# PIC32MZ2051W104132 device description
Architecture: MIPS; Family: PIC32MZW; Series: PIC32MZW
Registers are 32-bit, read-write, no defined reset value unless marked. A register's access mark holds for its fields unless they carry their own. Offsets are from the block's base; [hi:lo] are bit positions; {n}, {i} and the like mark numbered series.

## CRU
Instances: CRU 0x1f801200 in periph_pb1a
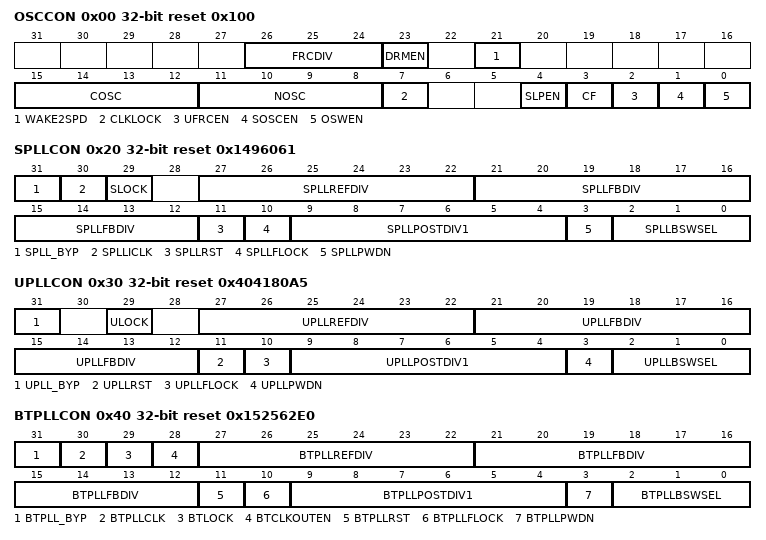
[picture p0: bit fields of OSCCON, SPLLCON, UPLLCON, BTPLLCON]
0x00 OSCCON reset 0x100 — CRU OSCILLATOR CONTROL REGISTER
  [26:24] FRCDIV — Fast RC Clock Divider bits
    0=OSC_FRC_DIV_1 (FRC Divide by 1); 1=OSC_FRC_DIV_2 (FRC Divide by 2); 2=OSC_FRC_DIV_4 (FRC Divide by 4); 3=OSC_FRC_DIV_8 (FRC Divide by 8); 4=OSC_FRC_DIV_16 (FRC Divide by 16); 5=OSC_FRC_DIV_32 (FRC Divide by 32); 6=OSC_FRC_DIV_64 (FRC Divide by 64); 7=OSC_FRC_DIV_256 (FRC Divide by 256)
  [23] DRMEN — Enable Dream Mode bit
    1=SLEEP (When the cpu_si_sleep input is asserted and SLPEN = 1, DMA transfer complete causes SLEEP Mode to be entered); 0=NO_EFFECT (DMA transfer has no effect)
  [21] WAKE2SPD — 2-Speed startup enabled in Sleep mode bit
    1=FRC (When the device EXITS Sleep Mode, the sys_clk will be from FRC until the selected clock is ready); 0=SELECTED_CLK (When the device EXITS Sleep Mode, the sys_clk will be from the selected clock.)
  [15:12] COSC — Current Oscillator Selection bits (Read-only)
    0=FRC (Fast RC Oscillator (FRC) divided by OSCCON.FRCDIV (Supports FRC/16 and FRC/1)); 1=SPLL (System PLL (SPLL Module) (input clock and divider set by SPLLCON)); 2=POSC (Primary Oscillator- POSC); 3=UPLL (USB PLL (UPLL Module) (input clock and divider set by UPLLCON)); 4=SOSC (Secondary Oscillator (SOSC)); 5=LPRC (Low Power RC Oscillator (LPRC)); 6=BTCLK (BT PLL (input clock and divider set by BTPLLCON)); 7=ECLK (EWPLL Ethernet Clock (input clock and divider set by EWPLLCON)); 8=WCLK (EWPLL WiFi Clock (input clock and divider set by EWPLLCON))
  [11:8] NOSC — New Oscillator Selection bits
    0=FRCCLK (Fast RC Oscillator (FRC) divided by OSCCON.FRCDIV ( Supports FRC/16 and FRC/1)); 1=SPLL (SPLL Module (input clock and divider set by SPLLCON)); 2=POSC (Primary Oscillator); 3=USBCLK (UPLL mode (input clock divider set by UPLLCON) -- was POSC with PLL); 4=SOSC (Secondary Oscillator (SOSC)); 5=LPRC (Low Power RC Oscillator (LPRC)); 6=BTCLK (BT PLL (input clock and divider set by BTPLLCON)); 7=ECLK (EWPLL Ethernet Clock (input clock and divider set by EWPLLCON)); 8=WCLK (EWPLL WiFi Clock (input clock and divider set by EWPLLCON))
  [7] CLKLOCK — Clock Lock Enabled bit
    1=LOCKED (All clock and PLL configuration registers are locked. These include OSCCON, OSCTRIM, SPLLCON, UPLLCON, PBxDIV); 0=UNLOCKED (Clock and PLL selection registers are not locked, configurations may be modified)
  [4] SLPEN — Enable SLEEP Mode bit
    1=SLEEP (When a WAIT Instruction is executed device will enter SLEEP Mode); 0=IDLE (When a WAIT instruction is executed device will enter IDLE Mode)
  [3] CF — Clock Fail Detect bit (Read / writable / Clearable by application)
    1=FAIL_DET (FSCM has detected clock failure); 0=NO_FAILDET (FSCM has not detected clock failure)
  [2] UFRCEN — USB FRC Clock Enable bit
    1=FRC (Enable FRC as the clock source for the USB clock source); 0=USBCLK (Use the primary oscillator or UPLL as the USB clock source)
  [1] SOSCEN — 32 kHz Secondary (LP) Oscillator Enable bit
    1=ON (Enable Secondary Oscillator); 0=OFF (Disable Secondary Oscillator)
  [0] OSWEN — Oscillator Switch Enable bit
    1=SWITCH (Request oscillator switch to selection specified by NOSC[3:0] bits); 0=SWITCH_COMPLETE (Oscillator switch is complete)
0x10 OSCTUN reset 0x0 — CRU OSCILLATOR TRIMMING REGISTER
  [5:0] TUN — Internal Fast RC (FRC) Oscillator Tuning bits
    31=Maximum Frequency; 0=Center Frequency, oscillator is running at calibrated frequency; 32=Minimum Frequency
0x20 SPLLCON reset 0x1496061 — SPLL CONTROL REGISTER
  [31] SPLL_BYP — SPLL Bypass
    1=BYPASS (The input clock REF bypasses PLL to PLLOUTx); 0=NO_BYPASS (The input clock REF does not bypass PLL to PLLOUTx)
  [30] SPLLICLK — Source Input Clock Selection bit
    0=POSC (POSC is the SPLL input clock source.); 1=FRC (FRC is the SPLL input clock source.)
  [29] SLOCK — System PLL Lock Status bit (Read-only)
    1=IN_LOCK (Indicates that SPLL is in lock.); 0=OUT_OF_LOCK (Indicates that SPLL is out of lock, start-up timer is in progress, or is turned-off.)
  [27:22] SPLLREFDIV — Reference Frequency Divide, 1 to 63
  [21:12] SPLLFBDIV — PLL feedback divider, 16 to 1023
  [11] SPLLRST — System PLL Reset
    1=ASSERT (Assert the reset to the SPLL); 0=NO_ASSERT (De-assert the reset to the SPLL)
  [10] SPLLFLOCK — System PLL Force Lock
    1=ASSERT (Force the SPLL lock signal to be asserted); 0=NO_ASSERT (Do not force the SPLL lock signal to be asserted)
  [9:4] SPLLPOSTDIV1 — First Post Divide Value, 1 to 63
  [3] SPLLPWDN — PLL Power Down Register bit
    1=PLL_OFF (PLL is powered down); 0=PLL_ON (PLL is active)
  [2:0] SPLLBSWSEL — PLL Bandwidth Select
0x30 UPLLCON reset 0x404180A5 — UPLL CONTROL REGISTER
  [31] UPLL_BYP — UPLL Bypass
    1=POSC (the input clock REF bypasses PLL to PLLOUTx); 0=UPLL (the input clock REF does not bypass PLL to PLLOUTx)
  [29] ULOCK — USB PLL Lock Status bit (Read-only)
    1=Indicates that UPLL is in lock; 0=Indicates that UPLL is out of lock, start-up timer is in progress, or is turned-off
  [27:22] UPLLREFDIV — Reference Frequency Divide. 1 to 63
  [21:12] UPLLFBDIV — PLL feedback divider, 16 to 1023
  [11] UPLLRST — USB PLL Reset
    1=ASSERT_RST (Assert the reset to the UPLL); 0=DEASSERT_RST (De-assert the reset to the UPLL)
  [10] UPLLFLOCK — USB PLL Force Lock
    1=FORCE_LOCK (Force the UPLL lock signal to be asserted); 0=NOFORCE_LOCK (Do not force the UPLL lock signal to be asserted)
  [9:4] UPLLPOSTDIV1 — First Post Divide Value, 1 to 63
  [3] UPLLPWDN — PLL Power Down Register bit
    1=PLL_OFF (PLL is powered down); 0=PLL_ON (PLL is active)
  [2:0] UPLLBSWSEL — USB PLL Bandwidth Select
0x40 BTPLLCON reset 0x152562E0 — BTPLL CONTROL REGISTER
  [31] BTPLL_BYP — BTPLL Bypass
    1=BYPASS (input clock REF bypasses PLL to PLLOUTx); 0=NO_BYPASS (input clock REF does not bypass PLL to PLLOUTx)
  [30] BTPLLCLK — Source Input Clock Selection bit
    0=POSC (POSC is the BTPLL input clock source.); 1=FRC (FRC is the BTPLL input clock source.)
  [29] BTLOCK — BT PLL Lock Status bit (Read-only)
    1=Indicates that BTPLL is in lock; 0=Indicates that BTPLL is out of lock, start-up timer is in progress, or is turned-off
  [28] BTCLKOUTEN — BT Clock Out pin Enable Bit
    1=ENABLED (BT_CLK_OUT Pin is enabled); 0=DISABLED (BT_CLK_OUT Pin is disabled)
  [27:22] BTPLLREFDIV — Reference Frequency Divide
  [21:12] BTPLLFBDIV — PLL feedback divider
  [11] BTPLLRST — BT PLL Reset
    1=ASSERT (Assert the reset to the BTPLL); 0=DEASSERT (De-assert the reset to the BTPLL)
  [10] BTPLLFLOCK — BT PLL Force Lock
    1=FORCE (Force the BTPLL lock signal to be asserted); 0=NO_FORCE (Do not force the BTPLL lock signal to be asserted)
  [9:4] BTPLLPOSTDIV1 — First Post Divide Value. 1 to 63
  [3] BTPLLPWDN — PLL Power Down Register bit
    1=PLL_OFF (PLL is powered down); 0=PLL_ON (PLL is active)
  [2:0] BTPLLBSWSEL — PLL Bandwidth Select
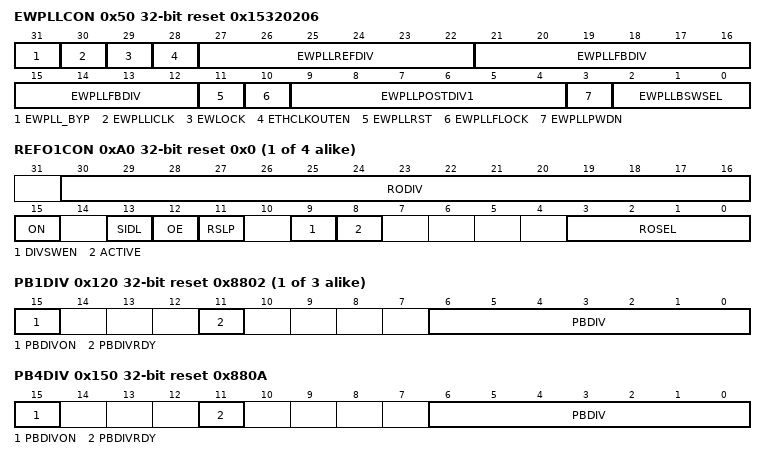
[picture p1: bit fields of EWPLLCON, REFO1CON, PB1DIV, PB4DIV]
0x50 EWPLLCON reset 0x15320206 — EWPLL CONTROL REGISTER
  [31] EWPLL_BYP — EWPLL Bypass
    1=BYPASS (the input clock REF bypasses PLL to PLLOUTx); 0=NO_BYPASS (the input clock REF does not bypass PLL to PLLOUTx)
  [30] EWPLLICLK — Source Input Clock Selection bit
    0=POSC (POSC is the EWPLL input clock source.); 1=FRC (FRC is the EWPLL input clock source.)
  [29] EWLOCK — EW PLL Lock Status bit (Read-only)
    1=Indicates that EWPLL is in lock; 0=Indicates that EWPLL is out of lock, start-up timer is in progress, or is turned-off
  [28] ETHCLKOUTEN — Ethernet Clock Out pin Enable Bit
    1=ENABLED (ETH_CLK_OUT Pin is enabled); 0=DISABLED (ETH_CLK_OUT Pin is disabled)
  [27:22] EWPLLREFDIV — Reference Frequency Divide
  [21:12] EWPLLFBDIV — PLL feedback divider
  [11] EWPLLRST — EW PLL Reset
    1=RESET_EWPLL (Assert the reset to the EWPLL); 0=NORESET_EWPLL (De-assert the reset to the EWPLL)
  [10] EWPLLFLOCK — EW PLL Force Lock
    1=FORCE_ASSERT (Force the EWPLL lock signal to be asserted); 0=NO_FORCE (Do not force the EWPLL lock signal to be asserted)
  [9:4] EWPLLPOSTDIV1 — First Post Divide Value
  [3] EWPLLPWDN — PLL Power Down Register bit
    1=PLL_OFF (PLL is powered down); 0=PLL_ON (PLL is active)
  [2:0] EWPLLBSWSEL — PLL Bandwidth Select
{0x80+0x20*i} REFO{i}CON reset 0x0 (i=1..4) — REFERENCE OSCILLATOR {i} CONTROL REGISTER
  [30:16] RODIV — Reference Clock Divider bits
    0x7fff=REFO1 clock is Base clock frequency divided by 65,534 (32,767 *2); 2=REFO1 clock is Base clock frequency divided by 4 (2*2); 1=REFO1 clock is Base clock frequency divided by 2 (1*2); 0=REFO1 clock is same frequency as Base clock (no divider)
  [15] ON — Output Enable bit
    1=Reference Oscillator Module enabled; 0=Reference Oscillator Module disabled
  [13] SIDL — Peripheral Stop in Idle Mode bit
    1=Discontinue module operation when device enters Idle mode; 0=Continue module operation in Idle mode
  [12] OE — Reference Clock Output Enable bit
    1=Reference clock is driven out on REFO1 pin; 0=Reference clock is not driven out on REFO1 pin
  [11] RSLP — Reference Oscillator Run in Sleep bit
    1=Reference Oscillator output continues to run in Sleep; 0=Reference Oscillator output is disabled in Sleep
  [9] DIVSWEN — Clock RODIV/ROTRIM switch enabled.
    1=Clock Divider Switching currently in progress; 0=Clock Divider Switch has completed
  [8] ACTIVE — Reference Clock Request Status bit
    1=Reference clock request is active (User should not update this REFOCON register); 0=Reference clock request is not active (User can update this REFOCON register)
  [3:0] ROSEL — Reference Clock Source Select bits
    11=REFCLKIx (REFI Pin); 10=BTPLL (BTPLL Clock); 9=WCLK (EWPLL WiFi Clock); 8=ECLK (EWPLL Ethernet Clock); 7=SPLL (System PLL); 6=UPLL (USB PLL); 5=SOSC; 4=LPRC; 3=FRC; 2=POSC; 1=PBCLK (Peripheral clock (reference clock reflects any peripheral clock switching)); 0=SYSCLK (System clock (reference clock reflects any device clock switching))
{0x90+0x20*i} REFO{i}TRIM reset 0x0 (i=1..4) — REFERENCE OSCILLATOR {i} TRIM REGISTER
  [31:23] ROTRIM — Trim bits - Provides fractional additive to RODIV value for 1/2 period of REFO1 clock
    0=0/512 (0.0) divisor added to RODIV value; 1=1/512 (0.001953125) divisor added to RODIV value; 2=2/512 (0.00390625) divisor added to RODIV value; 0x100=256/512 (0.5000) divisor added to RODIV value; 0x1ff=511/512 (0.998046875) divisor added to RODIV value
{0x110+0x10*i} PB{i}DIV reset 0x8802 (i=1..3) — PB{i} CLOCK DIVISOR CONTROL REGISTER
  [15] PBDIVON — Output Enable bit
    1=PB{i} Output clock is enabled; 0=PB{i} Output clock is disabled
  [11] PBDIVRDY — PB{i} Peripheral Clock Divisor Ready
    1=Indicates the PB clock divisor logic is not switching divisors and the PB{i}DIV may be written; 0=Indicates the PB clock divisor logic is currently switching values and the PB{i}DIV cannot be written
  [6:0] PBDIV — PB{i} Peripheral Clock Divisor Control value
    0=Divide by 1 PB{i} Clock same frequency as sys_clk; 1=Divide by 2 PB{i} Clock is 1/2 of sys_clk; 2=Divide by 3 PB{i} Clock is 1/3 of sys_clk; 15=Divide by 16 PB{i} Clock is 1/16 of sys_clk; 16=Divide by 17 PB{i} Clock is 1/17 of sys_clk; 126=Divide by 127 PB{i} Clock is 1/127 of sys_clk; 127=Divide by 128 PB{i} Clock is 1/128 of sys_clk
0x150 PB4DIV reset 0x880A — PB4 CLOCK DIVISOR CONTROL REGISTER
  [15] PBDIVON — Output Enable bit
    1=PB4 Output clock is enabled; 0=PB4 Output clock is disabled
  [11] PBDIVRDY — PB4 Peripheral Clock Divisor Ready
    1=Indicates the PB clock divisor logic is not switching divisors and the PB4DIV may be written; 0=Indicates the PB clock divisor logic is currently switching values and the PB4DIV cannot be written
  [6:0] PBDIV — PB4 Peripheral Clock Divisor Control value
    0=Divide by 1 PB4 Clock same frequency as sys_clk; 1=Divide by 2 PB4 Clock is 1/2 of sys_clk; 2=Divide by 3 PB4 Clock is 1/3 of sys_clk; 15=Divide by 16 PB4 Clock is 1/16 of sys_clk; 16=Divide by 17 PB4 Clock is 1/17 of sys_clk; 126=Divide by 127 PB4 Clock is 1/127 of sys_clk; 127=Divide by 128 PB4 Clock is 1/128 of sys_clk
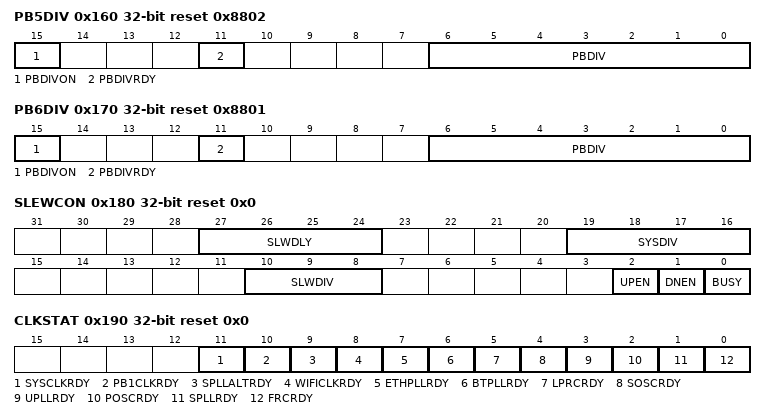
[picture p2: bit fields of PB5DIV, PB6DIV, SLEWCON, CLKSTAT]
0x160 PB5DIV reset 0x8802 — PB5 CLOCK DIVISOR CONTROL REGISTER
  [15] PBDIVON — Output Enable bit
    1=PB5 Output clock is enabled; 0=PB5 Output clock is disabled
  [11] PBDIVRDY — PB5 Peripheral Clock Divisor Ready
    1=Indicates the PB clock divisor logic is not switching divisors and the PB5DIV may be written; 0=Indicates the PB clock divisor logic is currently switching values and the PB5DIV cannot be written
  [6:0] PBDIV — PB5 Peripheral Clock Divisor Control value
    0=Divide by 1 PB5 Clock same frequency as sys_clk; 1=Divide by 2 PB5 Clock is 1/2 of sys_clk; 2=Divide by 3 PB5 Clock is 1/3 of sys_clk; 15=Divide by 16 PB5 Clock is 1/16 of sys_clk; 16=Divide by 17 PB5 Clock is 1/17 of sys_clk; 126=Divide by 127 PB5 Clock is 1/127 of sys_clk; 127=Divide by 128 PB5 Clock is 1/128 of sys_clk
0x170 PB6DIV reset 0x8801 — PB6 CLOCK DIVISOR CONTROL REGISTER
  [15] PBDIVON — Output Enable bit
    1=PB6 Output clock is enabled; 0=PB6 Output clock is disabled
  [11] PBDIVRDY — PB6 Peripheral Clock Divisor Ready
    1=Indicates the PB clock divisor logic is not switching divisors and the PB6DIV may be written; 0=Indicates the PB clock divisor logic is currently switching values and the PB6DIV cannot be written
  [6:0] PBDIV — PB6 Peripheral Clock Divisor Control value
    0=Divide by 1 PB6 Clock same frequency as sys_clk; 1=Divide by 2 PB6 Clock is 1/2 of sys_clk; 2=Divide by 3 PB6 Clock is 1/3 of sys_clk; 15=Divide by 16 PB6 Clock is 1/16 of sys_clk; 16=Divide by 17 PB6 Clock is 1/17 of sys_clk; 126=Divide by 127 PB6 Clock is 1/127 of sys_clk; 127=Divide by 128 PB6 Clock is 1/128 of sys_clk
0x180 SLEWCON reset 0x0 — SLEW RATE CONTROL FOR CLOCK SWITCHING REGISTER
  [27:24] SLWDLY — Number of clocks generated at each slew step for a clock switch
    0=1 clock will be generated at each slew step; {v}={v+1} clocks will be generated at each slew step (v=1..15)
  [19:16] SYSDIV — PBx Peripheral Clock Divisor Control value
    0=Divide by 1- sys_clk_out same frequency as sys_clk source - Default; {v}=Divide by {v+1}- sys_clk_out is 1/{v+1} of sys_clk source (v=1..15)
  [10:8] SLWDIV — Divisor steps used when doing slewed clock switches
    0=No Divisor used; 1=Divide by 2, then no divisor; 2=Divide by 4, then by 2, then no divisor; 3=Divide by 8, then by 4, then by 2, then no divisor; 4=Divide by 16, then by 8, then by 4, then by 2, then no divisor; 5=Divide by 32, then by 16, then by 8, then by 4, then by 2, then no divisor; 6=Divide by 64, then by 32, then by 16, then by 8, then by 4, then by 2, then no divisor; 7=Divide by 128, then by 64, then by 32, then by 16, then by 8, then by 4, then by 2, then no divisor
  [2] UPEN — Clock slew enable for switching up to faster clocks
    0=Clock Slewing disabled; 1=Clock Slewing enabled on a clock switch OR exit from SLEEP
  [1] DNEN — Clock slew enable for switching down to slower clocks
    0=Clock Slewing disabled; 1=Clock Slewing enabled on a clock switch
  [0] BUSY — Clock Switch Slewing Active Status Bit - Read-Only
    0=Clock Switch has reached its final value; 1=Clock frequency is being actively Slewed
0x190 CLKSTAT reset 0x0 — CLOCK STATUS REGISTER
  [11] SYSCLKRDY — System Clock Ready Status value
    0=SYSCLK is not stable and not ready; 1=SYSCLK is stable and ready
  [10] PB1CLKRDY — PB1 Clock Ready Status value
    0=PB1CLK is not stable and not ready; 1=PB1CLK is stable and ready
  [9] SPLLALTRDY — System PLL Ready Status value
    0=SPLL Alternate Output is not stable and not ready; 1=SPLL Alternate Output is stable and ready
  [8] WIFICLKRDY — WiFi Clock Ready Status value
    0=WIFICLK is not stable and not ready; 1=WIFICLK is stable and ready
  [7] ETHPLLRDY — EWPLL Ready Status value
    0=EWPLL is not stable and not ready; 1=EWPLL is stable and ready
  [6] BTPLLRDY — Bluetooth PLL Ready Status value
    0=BTPLL is not stable and not ready; 1=BTPLL is stable and ready
  [5] LPRCRDY — LPRC Ready Status value
    0=LPRC is not stable and not ready; 1=LPRC is stable and ready
  [4] SOSCRDY — SOSC Ready Status value
    0=SOSC is not stable and not ready; 1=SOSC is stable and ready
  [3] UPLLRDY — USB PLL Ready Status value
    0=UPLL is not stable and not ready; 1=UPLL is stable and ready
  [2] POSCRDY — Primary Oscillator Ready Status value
    0=POSC is not stable and not ready; 1=POSC is stable and ready
  [1] SPLLRDY — System PLL Ready Status value
    0=SPLL Primary Output is not stable and not ready; 1=SPLL Primary Output is stable and ready
  [0] FRCRDY — FRC Ready Status value
    0=FRC is not stable and not ready; 1=FRC is stable and ready
0x1A0 OSCCONBAR ro
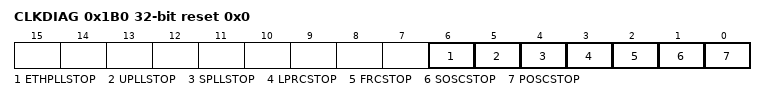
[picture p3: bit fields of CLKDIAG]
0x1B0 CLKDIAG reset 0x0 — USER CLK DIAGNOSTICS CONTROL REGISTER
  [6] ETHPLLSTOP — UPLL Clock Stop Control value
    0=EWPLL clock source runs as normal; 1=EWPLL clock source is stopped
  [5] UPLLSTOP — UPLL Clock Stop Control value
    0=UPLL clock source runs as normal; 1=UPLL clock source is stopped
  [4] SPLLSTOP — SPLL Clock Stop Control value
    0=SPLL clock source runs as normal; 1=SPLL clock source is stopped
  [3] LPRCSTOP — LPRC Clock Stop Control value
    0=LPRC clock source runs as normal; 1=LPRC clock source is stopped
  [2] FRCSTOP — FRC Clock Stop Control value
    0=FRC clock source runs as normal; 1=FRC clock source is stopped
  [1] SOSCSTOP — SOSC Clock Stop Control value
    0=SOSC clock source runs as normal; 1=SOSC clock source is stopped
  [0] POSCSTOP — POSC Clock Stop Control value
    0=POSC clock source runs as normal; 1=POSC clock source is stopped
Value list SPLLCON__SPLLPOSTDIV1: {v}=POSTDIV_{v} (First post divide by {v}) (v=1..63)
Value list SPLLCON__SPLLFBDIV: 16=DIV_16 (PLL feedback divide by 16); 17=DIV_17 (PLL feedback divide by 17); 18=DIV_18 (PLL feedback divide by 18); 0x3fe=DIV_1022 (PLL feedback divide by 1022); 0x3ff=DIV_1023 (PLL feedback divide by 1023)
Value list SPLLCON__SPLLREFDIV: {v}=REFDIV_{v} (Reference frequency divide by {v}) (v=1..63)
Value list UPLLCON__UPLLPOSTDIV1: {v}=First post divide by {v} (v=1..63)
Value list UPLLCON__UPLLREFDIV: {v}=Reference frequency divide by {v} (v=1..63)
Value list REFO1CON__FRZ: 1=When emulator is in Debug mode, module freezes operation; 0=When emulator is in Debug mode, module continues operation
